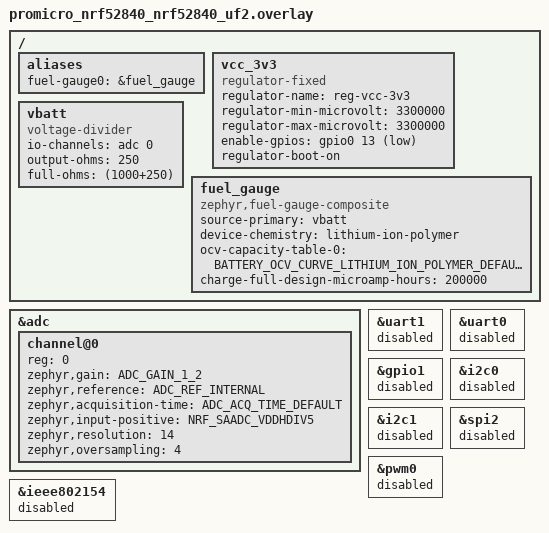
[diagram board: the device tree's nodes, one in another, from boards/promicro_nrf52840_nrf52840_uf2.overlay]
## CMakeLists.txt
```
cmake_minimum_required(VERSION 3.20.0)

find_package(Zephyr HINTS $ENV{ZEPHYR_BASE})
project(fruitytag)

target_include_directories(app PRIVATE src)

target_sources(app PRIVATE src/main.c)
target_sources(app PRIVATE src/tag/tag.c)
target_sources(app PRIVATE src/keystore/keystore.c)
target_sources(app PRIVATE src/fruitytag/fruitytag.c)

target_sources(app PRIVATE src/battery_thread/battery_thread.c)

target_sources(app PRIVATE src/blink_handler/blink_handler.c)

if(CONFIG_NRF52_ADAFRUIT_BOOTLOADER)
    target_sources(app PRIVATE src/adafruit_bootloader/adafruit_bootloader.c)
    target_sources(app PRIVATE src/adafruit_bootloader/ble_srv_ota_reset.c)
    target_sources(app PRIVATE src/adafruit_bootloader/dfu_cmds.c)
endif()

if(CONFIG_SHELL)
    target_sources(app PRIVATE src/cmds.c)
endif()
```

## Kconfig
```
# SPDX-License-Identifier: Apache-2.0

mainmenu "FruityTag"

# Your application configuration options go here

config NRF52_ADAFRUIT_BOOTLOADER
	bool "Enable flashing through adafruit-nrfutil"
	depends on SOC_SERIES_NRF52X
	select RETAINED_MEM
	default y if (!BOARD_HAS_NRF5_BOOTLOADER && BUILD_OUTPUT_UF2)
	help
	    Device must use Adafruit nRF52 Bootloader as a bootloader

config FRUITYTAG_ADVERTISEMENT_INTERVAL
    int "Advertisement interval"
    range 1 10000
    default 2000
    help
        The interval between advertisements in ms

rsource "src/fruitytag/Kconfig"
rsource "src/keystore/Kconfig"

source "Kconfig.zephyr"
```

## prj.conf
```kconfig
CONFIG_LOG=y
CONFIG_LOG_CMDS=y
CONFIG_LOG_BACKEND_SHOW_COLOR=y
CONFIG_LOG_MAX_LEVEL=1

CONFIG_REBOOT=y

CONFIG_BT=y
CONFIG_BT_PRIVACY=n
CONFIG_BT_PERIPHERAL=y
CONFIG_BT_DEVICE_NAME_DYNAMIC=y
CONFIG_BT_HCI_ERR_TO_STR=y
CONFIG_BT_BAS=y
CONFIG_BT_BAS_BLS=y

CONFIG_FLASH=y
CONFIG_FLASH_MAP=y

CONFIG_NVS=y
CONFIG_SETTINGS_NVS=y

CONFIG_SHELL=y
CONFIG_SHELL_HELP=y
CONFIG_SHELL_MINIMAL=y
CONFIG_SHELL_HISTORY=y
CONFIG_SHELL_METAKEYS=y
CONFIG_SHELL_VT100_COLORS=y

CONFIG_SETTINGS=y
CONFIG_SETTINGS_RUNTIME=y

CONFIG_BASE64=y
```

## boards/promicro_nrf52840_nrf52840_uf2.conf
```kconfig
CONFIG_NRF52_ADAFRUIT_BOOTLOADER=y

CONFIG_FUEL_GAUGE=y

CONFIG_SENSOR=y

CONFIG_PM_DEVICE=y

CONFIG_RAM_POWER_DOWN_LIBRARY=y
CONFIG_NCS_APPLICATION_BOOT_BANNER_STRING="FruityTag"

CONFIG_CDC_ACM_DTE_RATE_CALLBACK_SUPPORT=y

CONFIG_REGULATOR=y

CONFIG_BT_CTLR_TX_PWR_PLUS_8=y
```

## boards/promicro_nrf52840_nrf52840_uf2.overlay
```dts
/delete-node/ &reserved_partition_0;
/delete-node/ &code_partition;
/delete-node/ &storage_partition;
/delete-node/ &boot_partition;
#include <nordic/nrf52840_partition_uf2_sdv7.dtsi>
#include <zephyr/dt-bindings/battery/battery.h>


/ {

    aliases {
        fuel-gauge0 = &fuel_gauge;
    };

	vcc_3v3: vcc_3v3 {
		compatible = "regulator-fixed";

		regulator-name = "reg-vcc-3v3";
		regulator-min-microvolt = <3300000>;
		regulator-max-microvolt = <3300000>;
        // Should be ACTIVE_HIGH but https://github.com/zephyrproject-rtos/zephyr/pull/89973 not in nrf-sdk yet
		enable-gpios = <&gpio0 13 GPIO_ACTIVE_LOW>;

		regulator-boot-on;
		status = "okay";
	};

	vbatt: vbatt {
		compatible = "voltage-divider";
		io-channels = <&adc 0>;
		// Multiply by 5 as we use NRF_SAADC_VDDHDIV5
        output-ohms = <250>;
        full-ohms = <(1000+250)>;
	};

	fuel_gauge: fuel_gauge {
		compatible = "zephyr,fuel-gauge-composite";
		source-primary = <&vbatt>;
		device-chemistry = "lithium-ion-polymer";
		ocv-capacity-table-0 = <BATTERY_OCV_CURVE_LITHIUM_ION_POLYMER_DEFAULT>;
		charge-full-design-microamp-hours = <200000>;
	};
};

&adc {
    #address-cells = <1>;
	#size-cells = <0>;

	channel@0 {
        // Channel used for vbatt
		reg = <0>;
		zephyr,gain = "ADC_GAIN_1_2";
		zephyr,reference = "ADC_REF_INTERNAL";
		zephyr,acquisition-time = <ADC_ACQ_TIME_DEFAULT>;
		zephyr,input-positive = <NRF_SAADC_VDDHDIV5>;
		zephyr,resolution = <14>;
		zephyr,oversampling = <4>;
	};

	status = "okay";
};

&uart1 {
    status = "disabled";
};

&uart0 {
    status = "disabled";
};

&gpio1 {
    status = "disabled";
};

&i2c0 {
    status = "disabled";
};

&i2c1 {
    status = "disabled";
};

&spi2 {
    status = "disabled";
};

&pwm0 {
	status = "disabled";
};

&ieee802154 {
    status = "disabled";
};
```

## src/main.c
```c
#include "app_version.h"
#include "blink_handler/blink_handler.h"
#include "blink_timings.h"
#include "fruitytag/fruitytag.h"
#include "keystore/keystore.h"
#include <stdio.h>

#ifdef CONFIG_RAM_POWER_DOWN_LIBRARY
#include <ram_pwrdn.h>
#endif

#include "battery_thread/battery_thread.h"
#include <stdlib.h>
#include <zephyr/bluetooth/bluetooth.h>
#include <zephyr/bluetooth/conn.h>
#include <zephyr/bluetooth/controller.h>
#include <zephyr/bluetooth/hci.h>
#include <zephyr/kernel.h>
#include <zephyr/logging/log.h>
#include <zephyr/settings/settings.h>

LOG_MODULE_REGISTER(app);

static fruity_tag tag;

int main(void) {
  int err;

  printk("FruityTag v%s\n", APP_VERSION_STRING); // Using printk so it will always be shown

  uint8_t* pub_key = malloc(KEYSTORE_PUBKEY_SIZE);
  char bt_name[13];

  struct led_timing* blink_timing = &error_blink_timing;

  err = settings_subsys_init();
  if (err) {
    LOG_ERR("Couldn't initialize settings subsys: %d", err);
    goto blink_and_exit;
  }

  err = keystore_register();
  if (err) {
    LOG_ERR("Couldn't register keystore: %d", err);
    goto blink_and_exit;
  }

  err = settings_load();
  if (err) {
    LOG_ERR("Couldn't load settings: %d", err);
    goto blink_and_exit;
  }

  err = keystore_get_pubkey(pub_key, KEYSTORE_PUBKEY_SIZE);
  if (err == -ENOENT) {
    LOG_ERR("Device not setup yet. Setup using `fruitytag key set <base64 key>`");
    blink_timing = &not_setup_blink_timing;
    goto blink_and_exit;
  }

  err = fruitytag_init(&tag, CONFIG_FRUITYTAG_ADVERTISEMENT_INTERVAL);
  if (err) {
    LOG_ERR("Couldn't initalize fruity tag: %d", err);
    goto blink_and_exit;
  }

  err = fruitytag_update_pubkey(&tag, pub_key, KEYSTORE_PUBKEY_SIZE);
  if (err) {
    LOG_ERR("Couldn't update fruity tag: %d", err);
    goto blink_and_exit;
  }

  err = bt_enable(NULL);
  if (err) {
    LOG_ERR("Couldn't enable ble: %d", err);
    goto blink_and_exit;
  }

  snprintf(bt_name, sizeof(bt_name), "FruityTag-%02x", pub_key[0]);
  err = bt_set_name(bt_name);
  if (err) {
    LOG_ERR("Couldn't set name to %s", bt_name);
    goto blink_and_exit;
  }
  LOG_INF("name: %s", bt_name);

  err = fruitytag_start(&tag, true);
  if (err) {
    LOG_ERR("Couldn't start advertising: %d", err);
    goto blink_and_exit;
  }
  blink_timing = &ok_blink_timing;

blink_and_exit:
  free(pub_key);
  blink_handler_set_pattern(blink_timing);

#ifdef CONFIG_RAM_POWER_DOWN_LIBRARY
  power_down_unused_ram();
#endif

  return 0;
}

static void bt_connected(struct bt_conn* conn, uint8_t err) {
  if (err) {
    LOG_ERR("Connection failed, err 0x%02x %s", err, bt_hci_err_to_str(err));
  } else {
    LOG_INF("Connected");
    blink_handler_set_pattern(&connected_blink_timing);
  }
}

static void bt_disconnected(struct bt_conn* conn, uint8_t reason) {
  LOG_INF("Disconnected, reason 0x%02x %s", reason, bt_hci_err_to_str(reason));
}

static void bt_recycled() {
  int err;
  err = fruitytag_start(&tag, true);
  if (err) {
    LOG_ERR("Couldn't readvertise tag: %d", err);
    blink_handler_set_pattern(&error_blink_timing);
    return;
  }
  blink_handler_set_pattern(&ok_blink_timing);
}

BT_CONN_CB_DEFINE(conn_callbacks) = {
  .connected = bt_connected,
  .disconnected = bt_disconnected,
  .recycled = bt_recycled,
};

K_THREAD_DEFINE(battery_thread_id, 1024, battery_thread, &tag, NULL, NULL, 7, 0, 0);
```

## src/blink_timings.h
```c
#include "blink_handler/blink_handler.h"

struct led_timing error_blink_timing = {
  .time_on_ms = 100,
  .time_off_ms = 100
};

struct led_timing not_setup_blink_timing = {
  .time_on_ms = 1000,
  .time_off_ms = 0
};

struct led_timing ok_blink_timing = {
  .time_on_ms = 100,
  .time_off_ms = 15000
};

struct led_timing connected_blink_timing = {
  .time_on_ms = 500,
  .time_off_ms = 500
};
```

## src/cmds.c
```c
#include "keystore/keystore.h"
#include <stdlib.h>
#include <zephyr/kernel.h>
#include <zephyr/logging/log.h>
#include <zephyr/shell/shell.h>
#include <zephyr/sys/base64.h>
#include <zephyr/sys/reboot.h>

LOG_MODULE_REGISTER(fruitytag_cmd);
static uint8_t temp_pub_key[KEYSTORE_PUBKEY_SIZE];

static void reboot_in(uint8_t sec) {
  k_msleep(sec * 1000);

  LOG_INF("Rebooting");
  sys_reboot(SYS_REBOOT_COLD);
}

static int handle_set_public_key(const struct shell* shell, size_t argc, char** argv) {
  int err;
  size_t b64_buf_size;

  err = base64_decode(temp_pub_key, KEYSTORE_PUBKEY_SIZE, &b64_buf_size, argv[1], strlen(argv[1]));
  if (err == -EINVAL) {
    shell_error(shell, "Not a base64 string");
    return err;
  } else if (err) {
    shell_error(shell, "Unkown error occured during decoding: %d", err);
    return err;
  } else if (b64_buf_size != KEYSTORE_PUBKEY_SIZE) {
    shell_error(shell, "Base64 string must decode to %d bytes given: %d", KEYSTORE_PUBKEY_SIZE, b64_buf_size);
    return err;
  }

  shell_print(shell, "Saving to keystore");

  err = keystore_set_pubkey(temp_pub_key, KEYSTORE_PUBKEY_SIZE);
  if (err) {
    shell_error(shell, "Couldn't save public key: %d", err);
    return err;
  }

  shell_print(shell, "Saved.");
  shell_print(shell, "Rebooting in 2s.");
  reboot_in(2);
  return 0;
}

static int handle_get_public_key(const struct shell* shell, size_t argc, char** argv) {
  int err;
  size_t b64_buf_size;

  err = keystore_get_pubkey(temp_pub_key, sizeof(temp_pub_key));
  if (err == -ENOENT) {
    shell_error(shell, "Device not configured yet");
    return err;
  } else if (err) {
    shell_error(shell, "Couldn't load pubkey: %d", err);
    return err;
  }

  err = base64_encode(NULL, 0, &b64_buf_size, temp_pub_key, sizeof(temp_pub_key));
  if (err && err != -ENOMEM) { // No mem is expected as size = 0
    shell_error(shell, "Couldn't get base64 string size: %d", err);
    return err;
  }

  char base64_str[b64_buf_size];

  err = base64_encode(base64_str, b64_buf_size, &b64_buf_size, temp_pub_key, sizeof(temp_pub_key));
  if (err) {
    shell_error(shell, "Couldn't convert public key to base64 string");
    return err;
  }

  shell_print(shell, "Key: %s", base64_str);

  return 0;
}

static int handle_factory_reset(const struct shell* shell, size_t argc, char** argv) {
  int err;
  shell_print(shell, "Factory resetting");

  err = keystore_reset();
  if (err) {
    shell_error(shell, "Couldn't reset keystore: %d", err);
    return err;
  }

  shell_print(shell, "Rebooting in 2s");
  reboot_in(2);
  return 0;
}

SHELL_STATIC_SUBCMD_SET_CREATE(fruitytag_key,
                               SHELL_CMD_ARG(set, NULL, "set a new public key (base64)",
                                             handle_set_public_key, 2, 0),
                               SHELL_CMD_ARG(get, NULL, "get the current public key",
                                             handle_get_public_key, 1, 0),
                               SHELL_SUBCMD_SET_END);

SHELL_STATIC_SUBCMD_SET_CREATE(fruitytag_cmds,
                               SHELL_CMD_ARG(key, &fruitytag_key, "get/set public key",
                                             handle_set_public_key, 2, 0),
                               SHELL_CMD_ARG(reset, NULL, "factory resets the device", handle_factory_reset, 1, 0),
                               SHELL_SUBCMD_SET_END);
SHELL_CMD_REGISTER(fruitytag, &fruitytag_cmds, "FruityTag commands", NULL);
```

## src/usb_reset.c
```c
#include "adafruit_bootloader/adafruit_bootloader.h"
#include <zephyr/device.h>
#include <zephyr/drivers/uart/cdc_acm.h>
#include <zephyr/drivers/usb/usb_dc.h>

static void reset_into_dfu(const struct device* dev, uint32_t rate) {
  if (rate != 1200) {
    return;
  }

  // wait a bit before killing serial device so nrfutil doesn't complain
  k_msleep(10);

  usb_dc_detach();
  adafruit_reboot_into(DFU_MAGIC_SERIAL_ONLY_RESET);
}

static int usb_reset_init() {
  const struct device* dev = device_get_binding("board_cdc_acm_uart");

  if (dev == NULL) {
    return -ENODEV;
  }

  return cdc_acm_dte_rate_callback_set(dev, reset_into_dfu);
}

SYS_INIT(usb_reset_init, APPLICATION, 0);
```
